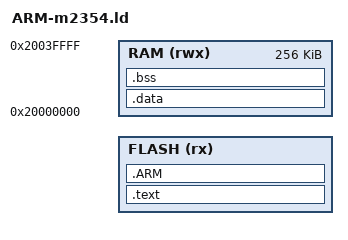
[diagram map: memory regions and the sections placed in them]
MEMORY
{
    FLASH (rx) : ORIGIN = @WOLFBOOT_TEST_APP_ADDRESS@, LENGTH = @WOLFBOOT_TEST_APP_SIZE@
    RAM (rwx) : ORIGIN = 0x20000000, LENGTH = 0x00040000 /* 256 KB SRAM */
}

SECTIONS
{
    .text :
    {
        _start_text = .;
        KEEP(*(.isr_vector))
        *(.text*)
        *(.rodata*)
        . = ALIGN(4);
        _end_text = .;
    } > FLASH

    .ARM :
    {
        __exidx_start = .;
        *(.ARM.exidx*)
        __exidx_end = .;
    } > FLASH

    _stored_data = .;
    .data : AT (_stored_data)
    {
        _start_data = .;
        KEEP(*(.data*))
        . = ALIGN(4);
        KEEP(*(.ramcode))
        . = ALIGN(4);
        _end_data = .;
    } > RAM

    .bss (NOLOAD) :
    {
        _start_bss = .;
        __bss_start__ = .;
        *(.bss*)
        *(COMMON)
        . = ALIGN(4);
        _end_bss = .;
        __bss_end__ = .;
        _end = .;
    } > RAM
    . = ALIGN(4);
    PROVIDE(_start_heap = _end);
    PROVIDE(_end_stack  = ORIGIN(RAM) + LENGTH(RAM));
}

END_STACK = ORIGIN(RAM) + LENGTH(RAM);
